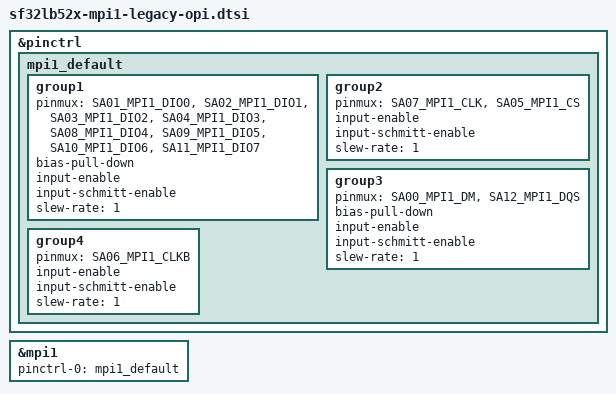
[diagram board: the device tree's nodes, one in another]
/*
 * Copyright (c) 2025 Core Devices LLC
 * Copyright (c) 2025 SiFli Technologies(Nanjing) Co., Ltd
 * SPDX-License-Identifier: Apache-2.0
 */

#include <zephyr/dt-bindings/pinctrl/sf32lb52x-pinctrl.h>

/*
 * MPI1 SiP Legacy OPI PSRAM pinmux (SDK func2, APS 32P LEGACY).
 * Legacy OPI uses DM (SA00), DQS (SA12) and CLKB (SA06) instead of
 * the Xccela/HyperBus DQSDM and analog SA00/SA06.
 * Used by: SF32LB523UB6, SF32LB52DUB6, SF32LB52EUB6.
 */

&pinctrl {
	mpi1_default: mpi1_default {
		group1 {
			pinmux = <SA01_MPI1_DIO0>, <SA02_MPI1_DIO1>,
				 <SA03_MPI1_DIO2>, <SA04_MPI1_DIO3>,
				 <SA08_MPI1_DIO4>, <SA09_MPI1_DIO5>,
				 <SA10_MPI1_DIO6>, <SA11_MPI1_DIO7>;
			bias-pull-down;
			input-enable;
			input-schmitt-enable;
			slew-rate = <1>;
		};

		group2 {
			pinmux = <SA07_MPI1_CLK>, <SA05_MPI1_CS>;
			input-enable;
			input-schmitt-enable;
			slew-rate = <1>;
		};

		/* DM and DQS are pulled down */
		group3 {
			pinmux = <SA00_MPI1_DM>, <SA12_MPI1_DQS>;
			bias-pull-down;
			input-enable;
			input-schmitt-enable;
			slew-rate = <1>;
		};

		group4 {
			pinmux = <SA06_MPI1_CLKB>;
			input-enable;
			input-schmitt-enable;
			slew-rate = <1>;
		};
	};
};

&mpi1 {
	pinctrl-0 = <&mpi1_default>;
	pinctrl-names = "default";
};
